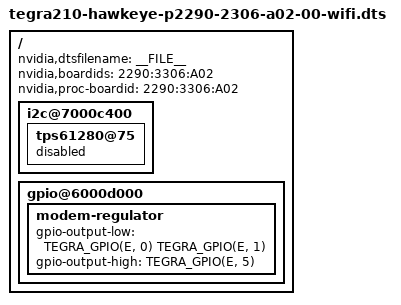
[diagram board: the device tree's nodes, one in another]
/*
 * Hawkeye P2290 A02 wifi FFD board.
 *	NVPN: 699-82290-2306-200
 *	variant: WWAN_3GB_F0_MP
 *	SKU: 3306
 *	assembly version: TM671D & Wi-Fi 
 *	LPDDR4 capacity: 3 GB
 *	optional features: no NFC + sensor hub + no barometer
 *	manufacturing phase : MP
 *
 * Copyright (c) 2015-2016, NVIDIA CORPORATION.  All rights reserved.
 *
 * This program is free software; you can redistribute it and/or modify
 * it under the terms of the GNU General Public License as published by
 * the Free Software Foundation; version 2 of the License.
 *
 * This program is distributed in the hope that it will be useful, but WITHOUT
 * ANY WARRANTY; without even the implied warranty of MERCHANTABILITY or
 * FITNESS FOR A PARTICULAR PURPOSE.  See the GNU General Public License for
 * more details.
 */

#include "tegra210-hawkeye-p2290-3306-a02-00-base.dts"

/ {
	nvidia,dtsfilename = __FILE__;
	nvidia,boardids = "2290:3306:A02";
	nvidia,proc-boardid = "2290:3306:A02";

	i2c@7000c400 {
		tps61280@75 {
			status = "disabled";
		};
	};

	gpio@6000d000 {
		modem-regulator {
			gpio-output-low = <TEGRA_GPIO(E, 0)
					   TEGRA_GPIO(E, 1)>;
			gpio-output-high = <TEGRA_GPIO(E, 5)>;
		};
	};
};
